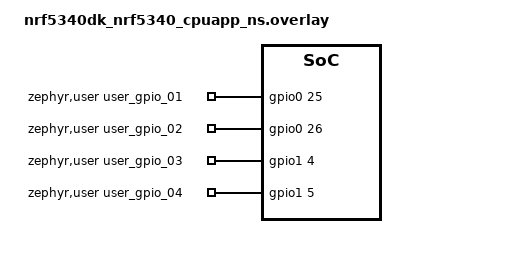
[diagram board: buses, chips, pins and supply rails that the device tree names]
// To get started, press Ctrl+Space to bring up the completion menu and view the available nodes.

// You can also use the buttons in the sidebar to perform actions on nodes.
// Actions currently available include:

// * Enabling / disabling the node
// * Adding the bus to a bus
// * Removing the node
// * Connecting ADC channels

// For more help, browse the DeviceTree documentation at https://docs.zephyrproject.org/latest/guides/dts/index.html
// You can also visit the nRF DeviceTree extension documentation at https://docs.nordicsemi.com/bundle/nrf-connect-vscode/page/guides/ncs_configure_app.html#devicetree-support-in-the-extension

/ {
	zephyr,user {
		user_gpio_01-gpios = <&gpio0 25 0>;
		user_gpio_02-gpios = <&gpio0 26 0>;
		user_gpio_03-gpios = <&gpio1 4 0>;
		user_gpio_04-gpios = <&gpio1 5 0>;
		//status = "okay";
	};
};

// &gpio0 {    //Enable gpio0 controller
//     status = "okay";
// };

// &gpio1 {    //Enable gpio0 controller
//     status = "okay";
// };
